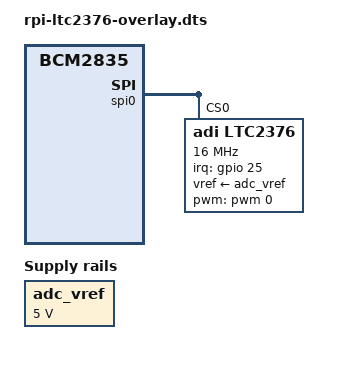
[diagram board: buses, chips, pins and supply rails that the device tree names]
/dts-v1/;
/plugin/;

#include <dt-bindings/interrupt-controller/irq.h>

/ {
	compatible = "brcm,bcm2835";

	fragment@0 {
		target = <&spidev0>;

		__overlay__ {
			status = "disabled";
		};
	};

	fragment@1 {
		target-path = "/";

		__overlay__ {
			adc_vref: fixedregulator@0 {
				compatible = "regulator-fixed";
				regulator-name = "fixed-supply";
				regulator-min-microvolt = <5000000>;
				regulator-max-microvolt = <5000000>;
				regulator-boot-on;
			};
		};
	};

	fragment@2 {
		target = <&spi0>;

		__overlay__{
			#address-cells = <1>;
			#size-cells = <0>;
			status = "okay";

			ltc2376@0{
				compatible = "adi,ltc2376";
				reg = <0>;
				spi-max-frequency = <16000000>;
				pwms = <&pwm 0 10000000>;
				vref-supply = <&adc_vref>;
				spi-cpha;
				spi-cpol;
				interrupt-parent = <&gpio>;
				interrupts = <25 IRQ_TYPE_EDGE_FALLING>;
			};
		};
	};
};
